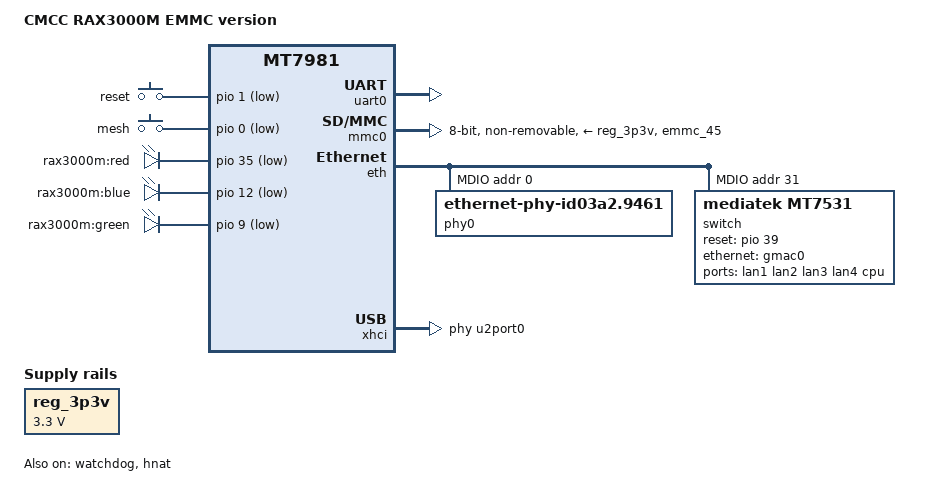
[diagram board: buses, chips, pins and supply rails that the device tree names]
/dts-v1/;
#include "mt7981.dtsi"
/ {
	model = "CMCC RAX3000M EMMC version";
	compatible = "cmcc,rax3000m-emmc", "mediatek,mt7981";

	aliases {
		led-boot = &red_led;
		led-failsafe = &red_led;
		led-running = &green_led;
		led-upgrade = &blue_led;
		serial0 = &uart0;
	};

	chosen {
		stdout-path = "serial0:115200n8";
		bootargs = "console=ttyS0,115200n1 loglevel=8  \
				earlycon=uart8250,mmio32,0x11002000 \
				root=PARTLABEL=rootfs rootwait rootfstype=squashfs,f2fs";
		};

	reg_3p3v: regulator-3p3v {
		compatible = "regulator-fixed";
		regulator-name = "fixed-3.3V";
		regulator-min-microvolt = <3300000>;
		regulator-max-microvolt = <3300000>;
		regulator-boot-on;
		regulator-always-on;
	};

	gl-hw {
		compatible = "gl-hw-info";
		model = "mt3000";
		wan = "eth1";
		lan = "eth0";
		usb-port = "1-1";
		flash_size = <65536>;
		temperature = "/sys/devices/virtual/thermal/thermal_zone0/temp";
		reset-button = "gpio-456";
		radio = "mt798111 mt798112";
		factory_data {
			device_mac = "/dev/mmcblk0p9", "0x0a";
			device_ddns = "/dev/mmcblk0p9", "0x10";
			device_sn_bak = "/dev/mmcblk0p9", "0x20";
			device_sn = "/dev/mmcblk0p9", "0x30";
			country_code = "/dev/mmcblk0p9", "0x88";
		};
	};

	gpio-keys {
		compatible = "gpio-keys";

		button-reset {
			label = "reset";
			linux,code = <KEY_RESTART>;
			gpios = <&pio 1 GPIO_ACTIVE_LOW>;
		};

		button-mesh {
			label = "mesh";
			linux,code = <BTN_9>;
			linux,input-type = <EV_SW>;
			gpios = <&pio 0 GPIO_ACTIVE_LOW>;
		};
	};
        
	leds {
		compatible = "gpio-leds";

		red_led: red {
			label = "rax3000m:red";
			gpios = <&pio 35 GPIO_ACTIVE_LOW>;
		};

		blue_led: blue {
			label = "rax3000m:blue";
			gpios = <&pio 12 GPIO_ACTIVE_LOW>;
		};

		green_led: green {
			label = "rax3000m:green";
			gpios = <&pio 9 GPIO_ACTIVE_LOW>;
		};
	};
};

&uart0 {
	status = "okay";
};

&watchdog {
	status = "okay";
};

&mmc0 {
         pinctrl-names = "default", "state_uhs";
         pinctrl-0 = <&mmc0_pins_default>;
         pinctrl-1 = <&mmc0_pins_uhs>;
         bus-width = <8>;
         max-frequency = <52000000>;
         cap-mmc-highspeed;
         vmmc-supply = <&reg_3p3v>;
         non-removable;
         status = "okay";
};

&eth {
	status = "okay";

	gmac0: mac@0 {
		compatible = "mediatek,eth-mac";
		reg = <0>;
		phy-mode = "2500base-x";

		fixed-link {
			speed = <2500>;
			full-duplex;
			pause;
		};
	};

	gmac1: mac@1 {
		compatible = "mediatek,eth-mac";
		reg = <1>;
		phy-mode = "gmii";
		phy-handle = <&phy0>;
	};

	mdio: mdio-bus {
		#address-cells = <1>;
		#size-cells = <0>;

		phy0: ethernet-phy@0 {
			compatible = "ethernet-phy-id03a2.9461";
			reg = <0>;
			phy-mode = "gmii";
			nvmem-cells = <&phy_calibration>;
			nvmem-cell-names = "phy-cal-data";
		};

		switch@0 {
			compatible = "mediatek,mt7531";
			reg = <31>;
			reset-gpios = <&pio 39 0>;

			ports {
				#address-cells = <1>;
				#size-cells = <0>;

				port@0 {
					reg = <0>;
					label = "lan1";
				};

				port@1 {
					reg = <1>;
					label = "lan2";
				};

				port@2 {
					reg = <2>;
					label = "lan3";
				};

				port@3 {
					reg = <3>;
					label = "lan4";
				};

				port@6 {
					reg = <6>;
					label = "cpu";
					ethernet = <&gmac0>;
					phy-mode = "2500base-x";

					fixed-link {
						speed = <2500>;
						full-duplex;
						pause;
					};
				};
			};
		};
	};
};

&hnat {
	mtketh-wan = "eth1";
	mtketh-lan = "eth0";
	mtketh-max-gmac = <2>;
	status = "okay";
};

&spi1 {
	pinctrl-names = "default";
	pinctrl-0 = <&spic_pins>;
	status = "disabled";
};

&pio {

	spic_pins: spi1-pins {
		mux {
			function = "spi";
			groups = "spi1_1";
		};
	};

	mmc0_pins_default: mmc0-pins-default {
		mux {
			function = "flash";
			groups = "emmc_45";
		};
	};

	mmc0_pins_uhs: mmc0-pins-uhs {
		mux {
			function = "flash";
			groups = "emmc_45";
		};
	};
};

&xhci {
	mediatek,u3p-dis-msk = <0x0>;
	phys = <&u2port0 PHY_TYPE_USB2>,
	       <&u3port0 PHY_TYPE_USB3>;
	status = "okay";
};
